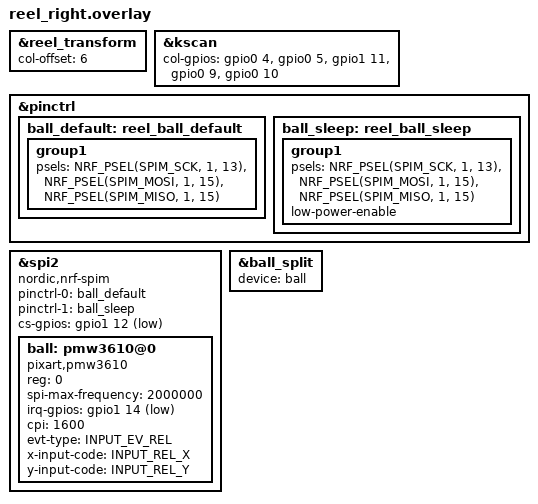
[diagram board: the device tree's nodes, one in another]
#include "reel_xiao.dtsi"
#include <zephyr/dt-bindings/input/input-event-codes.h>

&reel_transform { col-offset = <6>; };

&kscan {
    col-gpios = <&gpio0 4 GPIO_ACTIVE_HIGH>, <&gpio0 5 GPIO_ACTIVE_HIGH>,
                <&gpio1 11 GPIO_ACTIVE_HIGH>, <&gpio0 9 GPIO_ACTIVE_HIGH>,
                <&gpio0 10 GPIO_ACTIVE_HIGH>;
};

&pinctrl {
    ball_default: reel_ball_default {
        group1 {
            psels = <NRF_PSEL(SPIM_SCK, 1, 13)>, <NRF_PSEL(SPIM_MOSI, 1, 15)>,
                    <NRF_PSEL(SPIM_MISO, 1, 15)>;
        };
    };
    ball_sleep: reel_ball_sleep {
        group1 {
            psels = <NRF_PSEL(SPIM_SCK, 1, 13)>, <NRF_PSEL(SPIM_MOSI, 1, 15)>,
                    <NRF_PSEL(SPIM_MISO, 1, 15)>;
            low-power-enable;
        };
    };
};

&spi2 {
    status = "okay";
    compatible = "nordic,nrf-spim";
    pinctrl-0 = <&ball_default>;
    pinctrl-1 = <&ball_sleep>;
    pinctrl-names = "default", "sleep";
    cs-gpios = <&gpio1 12 GPIO_ACTIVE_LOW>;
    ball: pmw3610@0 {
        compatible = "pixart,pmw3610";
        reg = <0>;
        spi-max-frequency = <2000000>;
        irq-gpios = <&gpio1 14 (GPIO_ACTIVE_LOW | GPIO_PULL_UP)>;
        cpi = <1600>;
        evt-type = <INPUT_EV_REL>;
        x-input-code = <INPUT_REL_X>;
        y-input-code = <INPUT_REL_Y>;
    };
};

&ball_split {
    device = <&ball>;
    status = "okay";
};
